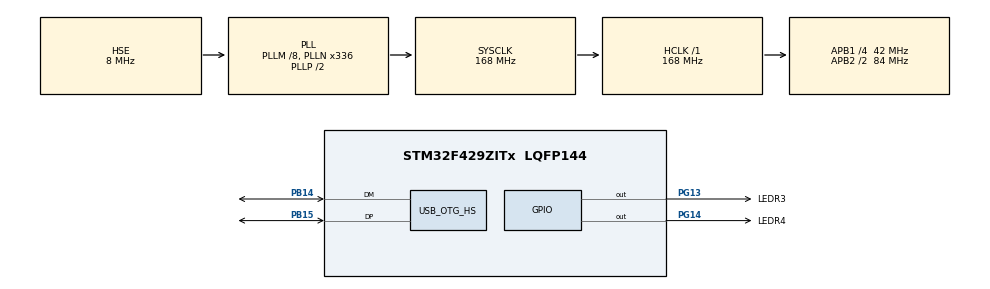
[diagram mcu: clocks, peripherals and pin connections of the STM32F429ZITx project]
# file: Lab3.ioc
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Mcu.Family=STM32F4
Mcu.Name=STM32F429ZITx
Mcu.Package=LQFP144
NVIC.OTG_HS_IRQn=true\:0\:0\:false\:false\:true\:true\:true\:true
NVIC.PriorityGroup=NVIC_PRIORITYGROUP_4
PB14.Mode=Device_Only_FS
PB14.Signal=USB_OTG_HS_DM
PB15.Mode=Device_Only_FS
PB15.Signal=USB_OTG_HS_DP
PG13.GPIO_Label=LEDR3
PG13.GPIO_Speed=GPIO_SPEED_FREQ_HIGH
PG13.Signal=GPIO_Output
PG14.GPIO_Label=LEDR4
PG14.GPIO_Speed=GPIO_SPEED_FREQ_HIGH
PG14.Signal=GPIO_Output
PH0/OSC_IN.Mode=HSE-External-Oscillator
PH0/OSC_IN.Signal=RCC_OSC_IN
PH1/OSC_OUT.Mode=HSE-External-Oscillator
PH1/OSC_OUT.Signal=RCC_OSC_OUT
ProjectManager.HeapSize=0x2000
ProjectManager.StackSize=0x400
ProjectManager.TargetToolchain=STM32CubeIDE
RCC.48MHZClocksFreq_Value=48000000
RCC.AHBFreq_Value=168000000
RCC.APB1CLKDivider=RCC_HCLK_DIV4
RCC.APB1Freq_Value=42000000
RCC.APB1TimFreq_Value=84000000
RCC.APB2CLKDivider=RCC_HCLK_DIV2
RCC.APB2Freq_Value=84000000
RCC.APB2TimFreq_Value=168000000
RCC.CortexFreq_Value=168000000
RCC.HCLKFreq_Value=168000000
RCC.HSE_VALUE=8000000
RCC.HSI_VALUE=16000000
RCC.LSE_VALUE=32768
RCC.PLLM=8
RCC.PLLN=336
RCC.PLLQ=7
RCC.SYSCLKFreq_VALUE=168000000
RCC.SYSCLKSource=RCC_SYSCLKSOURCE_PLLCLK
RCC.VCOOutputFreq_Value=336000000
USB_DEVICE.CLASS_NAME_HS=CDC
USB_DEVICE.VirtualMode-CDC_HS=Cdc
USB_DEVICE.VirtualModeHS=Cdc_HS
USB_OTG_HS.VirtualMode-Device_Only_FS=Device_Only_FS
VP_USB_DEVICE_VS_USB_DEVICE_CDC_HS.Mode=CDC_HS
board=custom

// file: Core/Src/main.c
/* USER CODE BEGIN Header */
/**
  ******************************************************************************
  * @file           : main.c
  * @brief          : Main program body
  ******************************************************************************
  * @attention
  *
  * Copyright (c) 2022 STMicroelectronics.
  * All rights reserved.
  *
  * This software is licensed under terms that can be found in the LICENSE file
  * in the root directory of this software component.
  * If no LICENSE file comes with this software, it is provided AS-IS.
  *
  ******************************************************************************
  */
/* USER CODE END Header */
#include "main.h"
#include <string.h>
#include "stm32f429i_discovery_lcd.h"
#include "usb_device.h"
#include "usbd_cdc_if.h"

void SystemClock_Config(void);
static void MX_GPIO_Init(void);

/* USER CODE BEGIN 0 */
uint8_t receive_data[64];
/* USER CODE END 0 */

int main(void)
{

  /* MCU Configuration--------------------------------------------------------*/

  /* Reset of all peripherals, Initializes the Flash interface and the Systick. */
  HAL_Init();

  /* Configure the system clock */
  SystemClock_Config();

  /* Initialize all configured peripherals */
  MX_GPIO_Init();
  MX_USB_DEVICE_Init();
  /* USER CODE BEGIN 2 */
  BSP_LCD_Init();//init LCD
  //set the layer buffer address into SDRAM
  BSP_LCD_LayerDefaultInit(1, SDRAM_DEVICE_ADDR);
  BSP_LCD_SelectLayer(1);//select on which layer we write
  BSP_LCD_DisplayOn();//turn on LCD
  BSP_LCD_Clear(LCD_COLOR_BLUE);//clear the LCD on blue color
  BSP_LCD_SetBackColor(LCD_COLOR_BLUE);//set text background color
  BSP_LCD_SetTextColor(LCD_COLOR_WHITE);//set text color
  //write text
  BSP_LCD_DisplayStringAtLine(0, (uint8_t*)"Good evening,");
  BSP_LCD_DisplayStringAtLine(1, (uint8_t*)" it's too dark");
  BSP_LCD_DisplayStringAtLine(2, (uint8_t*)" here");
  /* USER CODE END 2 */
  uint8_t a[64] = "Hello STM";
  uint8_t b[64] = "Turn on LED 3";
  uint8_t c[64] = "Turn on LED 4";
  uint8_t d[64] = "Turn off LED 3";
  uint8_t e[64] = "Turn off LED 4";
  uint8_t f[64] = "Good night";
  int i;
  /* Infinite loop */
  while (1)
  {
	  i = strcmp(a, receive_data);
	  if (i == 0){
		  BSP_LCD_DisplayStringAtLine(3, (uint8_t*)"Do you want to");
		  BSP_LCD_DisplayStringAtLine(4, (uint8_t*)" turn on light");
	  }

	  i = strcmp(b, receive_data);
	  if (i == 0) {HAL_GPIO_WritePin(GPIOG, GPIO_PIN_13, 1);}

	  i = strcmp(c, receive_data);
	  if (i == 0) {HAL_GPIO_WritePin(GPIOG, GPIO_PIN_14, 1);}

	  i = strcmp(d, receive_data);
	  if (i == 0) {HAL_GPIO_WritePin(GPIOG, GPIO_PIN_13, 0);}

	  i = strcmp(e, receive_data);
	  if (i == 0) {HAL_GPIO_WritePin(GPIOG, GPIO_PIN_14, 0);}

	  i = strcmp(f, receive_data);
	  if (i == 0) {
		  HAL_GPIO_WritePin(GPIOG, GPIO_PIN_13, 0);
		  HAL_GPIO_WritePin(GPIOG, GPIO_PIN_14, 0);
	  }
  }
}

void SystemClock_Config(void)
{
  RCC_OscInitTypeDef RCC_OscInitStruct = {0};
  RCC_ClkInitTypeDef RCC_ClkInitStruct = {0};

  /** Configure the main internal regulator output voltage
  */
  __HAL_RCC_PWR_CLK_ENABLE();
  __HAL_PWR_VOLTAGESCALING_CONFIG(PWR_REGULATOR_VOLTAGE_SCALE1);

  /** Initializes the RCC Oscillators according to the specified parameters
  * in the RCC_OscInitTypeDef structure.
  */
  RCC_OscInitStruct.OscillatorType = RCC_OSCILLATORTYPE_HSE;
  RCC_OscInitStruct.HSEState = RCC_HSE_ON;
  RCC_OscInitStruct.PLL.PLLState = RCC_PLL_ON;
  RCC_OscInitStruct.PLL.PLLSource = RCC_PLLSOURCE_HSE;
  RCC_OscInitStruct.PLL.PLLM = 8;
  RCC_OscInitStruct.PLL.PLLN = 336;
  RCC_OscInitStruct.PLL.PLLP = RCC_PLLP_DIV2;
  RCC_OscInitStruct.PLL.PLLQ = 7;
  if (HAL_RCC_OscConfig(&RCC_OscInitStruct) != HAL_OK)
  {
    Error_Handler();
  }

  /** Initializes the CPU, AHB and APB buses clocks
  */
  RCC_ClkInitStruct.ClockType = RCC_CLOCKTYPE_HCLK|RCC_CLOCKTYPE_SYSCLK
                              |RCC_CLOCKTYPE_PCLK1|RCC_CLOCKTYPE_PCLK2;
  RCC_ClkInitStruct.SYSCLKSource = RCC_SYSCLKSOURCE_PLLCLK;
  RCC_ClkInitStruct.AHBCLKDivider = RCC_SYSCLK_DIV1;
  RCC_ClkInitStruct.APB1CLKDivider = RCC_HCLK_DIV4;
  RCC_ClkInitStruct.APB2CLKDivider = RCC_HCLK_DIV2;

  if (HAL_RCC_ClockConfig(&RCC_ClkInitStruct, FLASH_LATENCY_5) != HAL_OK)
  {
    Error_Handler();
  }
}

static void MX_GPIO_Init(void)
{
  GPIO_InitTypeDef GPIO_InitStruct = {0};

  /* GPIO Ports Clock Enable */
  __HAL_RCC_GPIOH_CLK_ENABLE();
  __HAL_RCC_GPIOB_CLK_ENABLE();
  __HAL_RCC_GPIOG_CLK_ENABLE();

  /*Configure GPIO pin Output Level */
  HAL_GPIO_WritePin(GPIOG, LEDR3_Pin|LEDR4_Pin, GPIO_PIN_RESET);

  /*Configure GPIO pins : LEDR3_Pin LEDR4_Pin */
  GPIO_InitStruct.Pin = LEDR3_Pin|LEDR4_Pin;
  GPIO_InitStruct.Mode = GPIO_MODE_OUTPUT_PP;
  GPIO_InitStruct.Pull = GPIO_NOPULL;
  GPIO_InitStruct.Speed = GPIO_SPEED_FREQ_HIGH;
  HAL_GPIO_Init(GPIOG, &GPIO_InitStruct);

}

void Error_Handler(void)
{
  __disable_irq();
  while (1)
  {
  }
}
